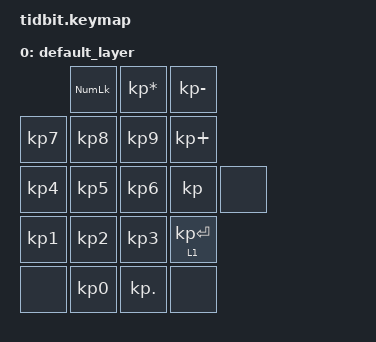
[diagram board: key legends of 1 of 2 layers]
/*
 * Copyright (c) 2020 The ZMK Contributors
 *
 * SPDX-License-Identifier: MIT
 */

#include <behaviors.dtsi>
#include <dt-bindings/zmk/bt.h>
#include <dt-bindings/zmk/outputs.h>
#include <dt-bindings/zmk/keys.h>

&encoder_1_top_row {
    status = "okay";
};

/ {
    keymap {
        compatible = "zmk,keymap";
        
        default_layer {
            bindings = <
                                &kp KP_NUMLOCK  &kp KP_ASTERISK &kp KP_MINUS
                &kp KP_NUMBER_7 &kp KP_NUMBER_8 &kp KP_NUMBER_9 &kp KP_PLUS
                &kp KP_NUMBER_4 &kp KP_NUMBER_5 &kp KP_NUMBER_6 &kp &none
                &kp KP_NUMBER_1 &kp KP_NUMBER_2 &kp KP_NUMBER_3 &lt 1 KP_ENTER
                &none           &kp KP_NUMBER_0 &kp KP_DOT      &none
            >;

            sensor-bindings = <&inc_dec_kp K_VOLUME_UP K_VOLUME_DOWN>;
        };

         func_layer {
             bindings = <
                            &none           &none &none
                &none       &bt BT_CLR_CMD  &none &out OUT_TOG
                &none       &bt BT_NXT_CMD  &none &out OUT_BLE
                &reset      &bt BT_PRV_CMD  &none &out OUT_USB
                &bootloader &bt BT_SEL_CMD  &none &tog 0
             >;

             sensor-bindings = <&inc_dec_kp K_VOLUME_UP K_VOLUME_DOWN>;
         };
    };
};
